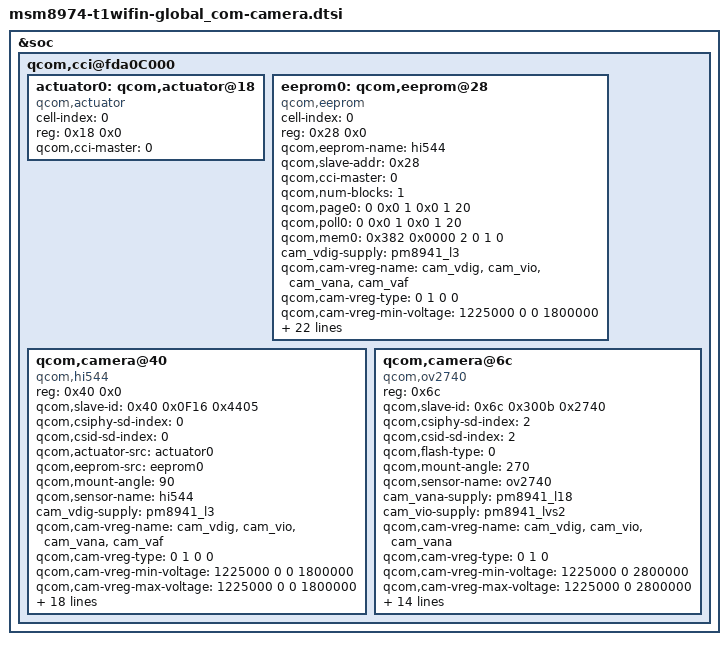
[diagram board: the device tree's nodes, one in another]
/*
 * Copyright (c) 2012, The Linux Foundation. All rights reserved.
 *
 * This program is free software; you can redistribute it and/or modify
 * it under the terms of the GNU General Public License version 2 and
 * only version 2 as published by the Free Software Foundation.
 *
 * This program is distributed in the hope that it will be useful,
 * but WITHOUT ANY WARRANTY; without even the implied warranty of
 * MERCHANTABILITY or FITNESS FOR A PARTICULAR PURPOSE.  See the
 * GNU General Public License for more details.
 */

/include/ "../../../skeleton.dtsi"

&soc {
	qcom,cci@fda0C000 {
		actuator0: qcom,actuator@18 {
			status = "ok";
			cell-index = <0>;
			reg = <0x18 0x0>;
			compatible = "qcom,actuator";
			qcom,cci-master = <0>;
		};

		eeprom0: qcom,eeprom@28 {
			cell-index = <0>;
			reg = <0x28 0x0>;
			qcom,eeprom-name = "hi544";
			compatible = "qcom,eeprom";
			qcom,slave-addr = <0x28>;
			qcom,cci-master = <0>;
			qcom,num-blocks = <1>;
			qcom,page0 = <0 0x0 1 0x0 1 20>;
			qcom,poll0 = <0 0x0 1 0x0 1 20>;
			qcom,mem0 = <0x382 0x0000 2 0 1 0>;

			cam_vdig-supply = <&pm8941_l3>;
			qcom,cam-vreg-name = "cam_vdig", "cam_vio", "cam_vana", "cam_vaf";
			qcom,cam-vreg-type = <0 1 0 0 >;
			qcom,cam-vreg-min-voltage = <1225000 0 0 1800000>;
			qcom,cam-vreg-max-voltage = <1225000 0 0 1800000>;
			qcom,cam-vreg-op-mode = <105000 0 0 100000>;
			qcom,gpio-no-mux = <0>;
			gpios = <&msmgpio 15 0>, 		// MCLK
				<&msmgpio 4 0>,			// MAIN_CAM_RESET
				<&msmgpio 16 0>,		// 13M_VANA_EN
				<&msmgpio 96 0>,		// 13M_VIO_EN
				<&msmgpio 57 0>;		// 13M_VCM_EN
			qcom,gpio-reset = <1>; 			// Set gpio_4 as reset
			qcom,gpio-vana = <2>;			// Set gpio_16 as VANA
			qcom,gpio-vio = <3>;			// Set gpio_96 as VIO
			qcom,gpio-vaf = <4>;			// Set gpio_57 as VCM
			qcom,gpio-req-tbl-num = <0 1 2 3 4>;
			qcom,gpio-req-tbl-flags = <0 0 0 0 0>;
			qcom,gpio-req-tbl-label =  "CAMIF_MCLK", "CAM_RESET1", "MAIN_VANA_EN", "MAIN_VIO_EN", "MAIN_VCM_EN";

			qcom,cam-power-seq-type = "sensor_gpio", "sensor_gpio", "sensor_vreg", "sensor_gpio", "sensor_gpio";
			qcom,cam-power-seq-val = "sensor_gpio_vio", "sensor_gpio_vana", "cam_vdig", "sensor_gpio_vaf", "sensor_gpio_reset";
			qcom,cam-power-seq-cfg-val = <1 1 0 1 1>;
			qcom,cam-power-seq-delay = <1 1 1 1 1>;
		};

		qcom,camera@40 {
			status = "ok";
			compatible = "qcom,hi544";
			reg = <0x40 0x0>;
			qcom,slave-id = <0x40 0x0F16 0x4405>;
			qcom,csiphy-sd-index = <0>;
			qcom,csid-sd-index = <0>;
			qcom,actuator-src = <&actuator0>;
			qcom,eeprom-src = <&eeprom0>;
			qcom,mount-angle = <90>;
			qcom,sensor-name = "hi544";
			cam_vdig-supply = <&pm8941_l3>;
			qcom,cam-vreg-name = "cam_vdig", "cam_vio", "cam_vana", "cam_vaf";
			qcom,cam-vreg-type = <0 1 0 0 >;
			qcom,cam-vreg-min-voltage = <1225000 0 0 1800000>;
			qcom,cam-vreg-max-voltage = <1225000 0 0 1800000>;
			qcom,cam-vreg-op-mode = <105000 0 0 100000>;
			qcom,gpio-no-mux = <0>;
			gpios = <&msmgpio 15 0>, 		// MCLK
				<&msmgpio 4 0>,			// MAIN_CAM_RESET
				<&msmgpio 16 0>,		// 13M_VANA_EN
				<&msmgpio 96 0>,		// 13M_VIO_EN
				<&msmgpio 57 0>;		// 13M_VCM_EN
			qcom,gpio-reset = <1>; 			// Set gpio_4 as reset
			qcom,gpio-vana = <2>;			// Set gpio_16 as VANA
			qcom,gpio-vio = <3>;			// Set gpio_96 as VIO
			qcom,gpio-vaf = <4>;			// Set gpio_57 as VCM
			qcom,gpio-req-tbl-num = <0 1 2 3 4>;
			qcom,gpio-req-tbl-flags = <0 0 0 0 0>;
			qcom,gpio-req-tbl-label =  "CAMIF_MCLK", "CAM_RESET1", "MAIN_VANA_EN", "MAIN_VIO_EN", "MAIN_VCM_EN";
			qcom,csi-lane-assign = <0x4320>;
			qcom,csi-lane-mask = <0x07>;
			qcom,sensor-position = <0>;
			qcom,sensor-mode = <1>;
			qcom,cci-master = <0>;
		};
		qcom,camera@6c {
			status = "ok";
			compatible = "qcom,ov2740";
			reg = <0x6c>;
			qcom,slave-id = <0x6c 0x300b 0x2740>;
			qcom,csiphy-sd-index = <2>;
			qcom,csid-sd-index = <2>;
			qcom,flash-type = <0>;
			qcom,mount-angle = <270>;
			qcom,sensor-name = "ov2740";
			cam_vana-supply = <&pm8941_l18>;
			cam_vio-supply = <&pm8941_lvs2>;
			qcom,cam-vreg-name = "cam_vdig", "cam_vio", "cam_vana";
			qcom,cam-vreg-type = <0 1 0>;
			qcom,cam-vreg-min-voltage = <1225000 0 2800000>;
			qcom,cam-vreg-max-voltage = <1225000 0 2800000>;
			qcom,cam-vreg-op-mode = <105000 0 80000>;
			qcom,gpio-no-mux = <0>;
			gpios = <&msmgpio 17 0>, //VT_CAM_MCLK
				<&msmgpio 18 0>, //VT_CAM_RESET
				<&msmgpio 30 0>; //VT_LDO_EN
			qcom,gpio-reset = <1>;
			qcom,gpio-vdig = <2>;
			qcom,gpio-req-tbl-num = <0 1 2>;
			qcom,gpio-req-tbl-flags = <0 0 0>;
			qcom,gpio-req-tbl-label = "CAMIF_MCLK2",
						     "CAM_RESET2",
						     "VT_LDO_EN";
			qcom,csi-lane-assign = <0x4320>;
			qcom,csi-lane-mask = <0x3>;
			qcom,sensor-position = <1>;
			qcom,sensor-mode = <1>;
			qcom,cci-master = <1>;
		};
	};
};
